VERSION "HIPBNYYYYYYYYYYYYYYYYYYYYYYYYYYYYYYYYYYYYY/4/%%%/4/'%**4YYY///"

NS_ :

BS_:

BU_:

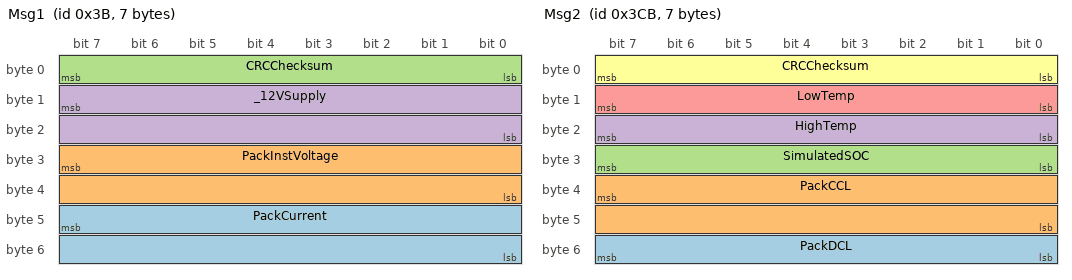
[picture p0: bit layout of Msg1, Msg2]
BO_ 59 Msg1: 7 Vector__XXX
 SG_ PackCurrent : 47|16@0+ (1,0) [0|0] "A" Vector__XXX
 SG_ PackInstVoltage : 31|16@0+ (0.1,0) [0|0] "V" Vector__XXX
 SG_ CRCChecksum : 7|8@0+ (1,66) [0|0] "" Vector__XXX
 SG_ _12VSupply : 15|16@0+ (0.001,0) [0|0] "V" Vector__XXX

BO_ 971 Msg2: 7 Vector__XXX
 SG_ PackDCL : 55|8@0+ (1,0) [0|0] "" Vector__XXX
 SG_ PackCCL : 39|16@0+ (1,0) [0|0] "" Vector__XXX
 SG_ SimulatedSOC : 31|8@0+ (1,0) [0|0] "%" Vector__XXX
 SG_ HighTemp : 23|8@0+ (1,0) [0|0] "C" Vector__XXX
 SG_ LowTemp : 15|8@0+ (1,0) [0|0] "C" Vector__XXX
 SG_ CRCChecksum : 7|8@0+ (1,981) [0|0] "" Vector__XXX

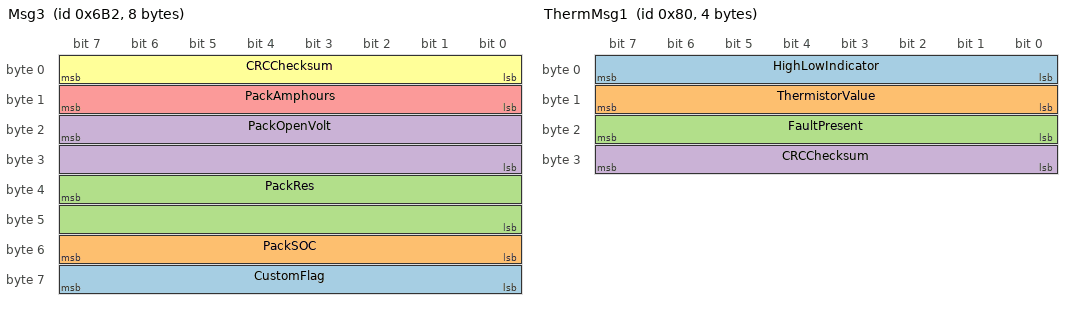
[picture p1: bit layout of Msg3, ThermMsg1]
BO_ 1714 Msg3: 8 Vector__XXX
 SG_ CustomFlag : 63|8@0+ (1,0) [0|0] "" Vector__XXX
 SG_ PackSOC : 55|8@0+ (0.5,0) [0|0] "%" Vector__XXX
 SG_ PackRes : 39|16@0+ (1,0) [0|0] "Ohms" Vector__XXX
 SG_ PackOpenVolt : 23|16@0+ (0.1,0) [0|0] "V" Vector__XXX
 SG_ PackAmphours : 15|8@0+ (0.05,0) [0|0] "Ah" Vector__XXX
 SG_ CRCChecksum : 7|8@0+ (1,1722) [0|0] "" Vector__XXX

BO_ 128 ThermMsg1: 4 Vector__XXX
 SG_ HighLowIndicator : 7|8@0+ (1,0) [0|0] "" Vector__XXX
 SG_ ThermistorValue : 15|8@0- (1,0) [0|0] "" Vector__XXX
 SG_ FaultPresent : 23|8@0+ (1,0) [0|0] "" Vector__XXX
 SG_ CRCChecksum : 31|8@0+ (1,0) [0|0] "" Vector__XXX

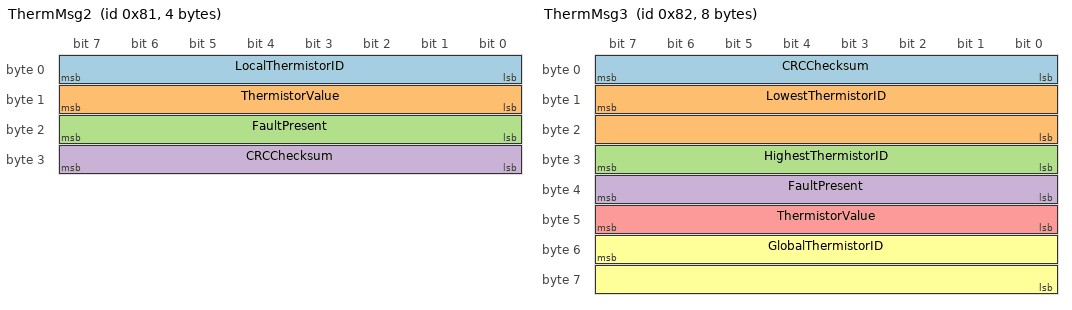
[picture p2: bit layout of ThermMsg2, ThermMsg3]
BO_ 129 ThermMsg2: 4 Vector__XXX
 SG_ LocalThermistorID : 7|8@0+ (1,0) [0|0] "" Vector__XXX
 SG_ ThermistorValue : 15|8@0+ (1,0) [0|0] "C" Vector__XXX
 SG_ FaultPresent : 23|8@0+ (1,0) [0|0] "" Vector__XXX
 SG_ CRCChecksum : 31|8@0+ (1,0) [0|0] "" Vector__XXX

BO_ 130 ThermMsg3: 8 Vector__XXX
 SG_ CRCChecksum : 7|8@0+ (1,0) [0|0] "" Vector__XXX
 SG_ LowestThermistorID : 15|16@0+ (1,1) [0|0] "" Vector__XXX
 SG_ HighestThermistorID : 31|8@0+ (1,0) [0|0] "" Vector__XXX
 SG_ FaultPresent : 39|8@0+ (1,0) [0|0] "" Vector__XXX
 SG_ ThermistorValue : 47|8@0+ (1,0) [0|0] "C" Vector__XXX
 SG_ GlobalThermistorID : 55|16@0+ (1,0) [0|0] "" Vector__XXX

VAL_ 1714 CustomFlag 0 "False" 1 "True" ;
VAL_ 128 HighLowIndicator 5 "Low" 6 "High" 7 "Low" 8 "High" ;
VAL_ 128 FaultPresent 1 "True" 0 "False" ;
VAL_ 129 LocalThermistorID 0 "First" 1 "Second" 2 "Third" 3 "Fourth" ;
VAL_ 129 FaultPresent 0 "False" 1 "True" ;
VAL_ 130 FaultPresent 0 "False" 1 "True" ;
